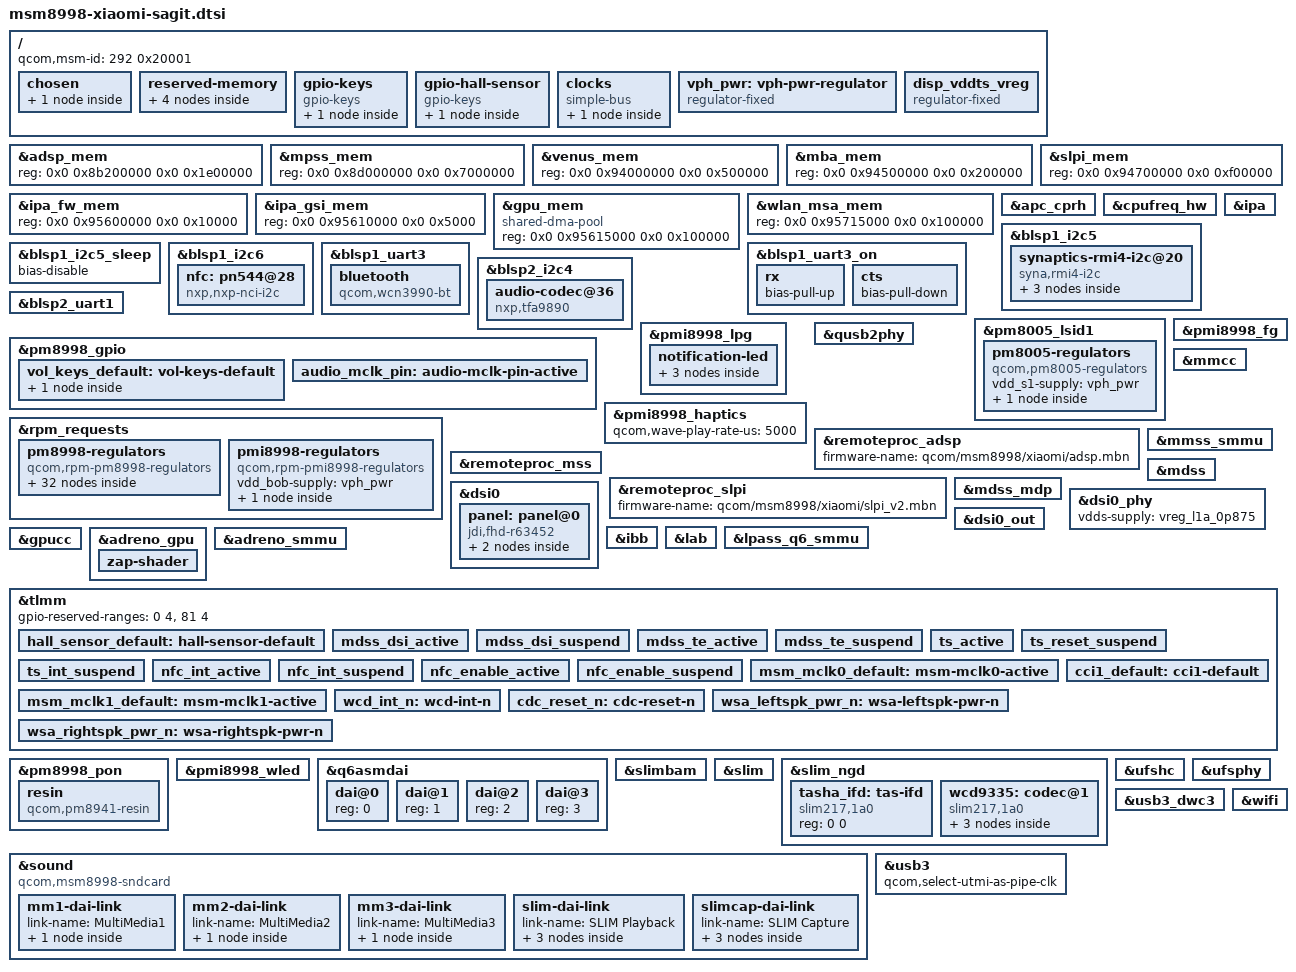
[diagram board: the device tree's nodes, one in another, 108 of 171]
// SPDX-License-Identifier: BSD-3-Clause
/*
 * Xiaomi Mi 6 (sagit) device tree source based on msm8998-mtp.dtsi
 *
 * Copyright (c) 2021, Degdag Mohamed <degdagmohamed@gmail.com>
 * Copyright (c) 2016, The Linux Foundation. All rights reserved.
 */

/dts-v1/;

#include "msm8998.dtsi"
#include "pm8005.dtsi"
#include "pm8998.dtsi"
#include "pmi8998.dtsi"
#include <dt-bindings/gpio/gpio.h>
#include <dt-bindings/input/input.h>
#include <dt-bindings/leds/common.h>
#include <dt-bindings/pinctrl/qcom,pmic-gpio.h>
#include <dt-bindings/sound/qcom,q6afe.h>
#include <dt-bindings/sound/qcom,q6asm.h>

/ {
	/* Required for bootloader to select correct board */
	qcom,msm-id = <292 0x20001>; /* 8998 v2.1 */

	chosen {
		#address-cells = <2>;
		#size-cells = <2>;
		ranges;

		/* Use display framebuffer setup by the UEFI XBL bootloader for simplefb */
		framebuffer0: framebuffer@9d400000 {
			compatible = "simple-framebuffer";
			reg = <0x0 0x9d400000 0x0 0x2400000>;
			width = <1080>;
			height = <1920>;
			stride = <(1080 * 4)>;
			format = "a8r8g8b8";
			status = "disabled";
		};
	};

	reserved-memory {
		/* Bootloader display framebuffer region */
		cont_splash_mem: memory@9d400000 {
			reg = <0x0 0x9d400000 0x0 0x2400000>;
			no-map;
		};

		/* For getting crash logs using Android downstream kernels */
		ramoops@ac000000 {
			compatible = "ramoops";
			reg = <0x0 0xac000000 0x0 0x200000>;
			console-size = <0x80000>;
			pmsg-size = <0x40000>;
			record-size = <0x8000>;
			ftrace-size = <0x20000>;
		};

		/*
		 * The following memory regions on downstream are "dynamically allocated"
		 * but given the same addresses every time. Hard code them as these addresses
		 * are where the Xiaomi signed firmware expects them to be.
		 */
		ipa_fws_region: ipa@f6800000 {
			compatible = "shared-dma-pool";
			reg = <0x0 0xf6800000 0x0 0x5000>;
			no-map;
		};
		zap_shader_region: gpu@f6900000 {
			compatible = "shared-dma-pool";
			reg = <0x0 0xf6900000 0x0 0x2000>;
			no-map;
		};
	};

	gpio-keys {
		compatible = "gpio-keys";
		label = "Volume buttons";
		autorepeat;

		pinctrl-names = "default";
		pinctrl-0 = <&vol_keys_default>;

		vol-down {
			label = "Volume up";
			gpios = <&pm8998_gpio 6 GPIO_ACTIVE_LOW>;
			linux,code = <KEY_VOLUMEUP>;
			debounce-interval = <15>;
			wakeup-source;
		};
	};

	gpio-hall-sensor {
		compatible = "gpio-keys";
		label = "Hall effect sensor";

		pinctrl-names = "default";
		pinctrl-0 = <&hall_sensor_default>;

		hall-sensor {
			label = "Hall Effect Sensor";
			gpios = <&tlmm 124 GPIO_ACTIVE_LOW>;
			linux,input-type = <EV_SW>;
			linux,code = <SW_LID>;
			linux,can-disable;
			wakeup-source;
		};
	};
	
	clocks {
		compatible = "simple-bus";

		div1_mclk: divclk1 {
			compatible = "gpio-gate-clock";
			pinctrl-0 = <&audio_mclk_pin>;
			pinctrl-names = "default";
			clocks = <&rpmcc RPM_SMD_DIV_CLK1>;
			#clock-cells = <0>;
			enable-gpios = <&pm8998_gpio 13 GPIO_ACTIVE_HIGH>;
		};
	};

	vph_pwr: vph-pwr-regulator {
		compatible = "regulator-fixed";
		regulator-name = "vph_pwr";
		regulator-always-on;
		regulator-boot-on;
	};
	
	disp_vddts_vreg: disp_vddts_vreg {
		compatible = "regulator-fixed";
		regulator-name = "disp_vddts_vreg";
		gpio = <&tlmm 50 GPIO_ACTIVE_HIGH>;
		enable-active-high;
		regulator-boot-on;
	};
};

/*
 * Xiaomi' ADSP firmware requires 30 MiB in total, so increase the adsp_mem
 * region by 4 MiB to account for this while relocating the other now
 * conflicting memory nodes accordingly.
 */
&adsp_mem {
	reg = <0x0 0x8b200000 0x0 0x1e00000>;
};
&mpss_mem {
	reg = <0x0 0x8d000000 0x0 0x7000000>;
};
&venus_mem {
	reg = <0x0 0x94000000 0x0 0x500000>;
};
&mba_mem {
	reg = <0x0 0x94500000 0x0 0x200000>;
};
&slpi_mem {
	reg = <0x0 0x94700000 0x0 0xf00000>;
};
&ipa_fw_mem {
	reg = <0x0 0x95600000 0x0 0x10000>;
};
&ipa_gsi_mem {
	reg = <0x0 0x95610000 0x0 0x5000>;
};
&gpu_mem {
	reg = <0x0 0x95615000 0x0 0x100000>;
};
&wlan_msa_mem {
	reg = <0x0 0x95715000 0x0 0x100000>;
};

&apc_cprh {
	status = "ok";
};

&cpufreq_hw {
	status = "ok";
};

&blsp1_i2c5 {
	pinctrl-names = "default", "sleep";
	pinctrl-0 = <&blsp1_i2c5_default>;
	pinctrl-1 = <&blsp1_i2c5_sleep>;
	clock-frequency = <400000>;
	status = "okay";

	synaptics-rmi4-i2c@20 {
		compatible = "syna,rmi4-i2c";
		reg = <0x20>;
		#address-cells = <1>;
		#size-cells = <0>;
		interrupts-extended = <&tlmm 125 0x2008>; /* 0x2008 = IRQF_ONESHOT | IRQF_TRIGGER_LOW */
		pinctrl-names = "default", "sleep";
		pinctrl-0 = <&ts_active>;
		pinctrl-1 = <&ts_int_suspend &ts_reset_suspend>;
		vdd-supply = <&disp_vddts_vreg>;
		vio-supply = <&vreg_l6a_1p8>;
		syna,reset-delay-ms = <200>;
		syna,startup-delay-ms = <200>;

		rmi4-f01@1 {
			reg = <0x01>;
			syna,nosleep-mode = <1>;
		};

		rmi4_f12: rmi4-f12@12 {
			reg = <0x12>;
			touchscreen-x-mm = <64>;
			touchscreen-y-mm = <114>;
			syna,sensor-type = <1>;
			syna,rezero-wait-ms = <200>;
		};
		
		rmi4-f1a@1a {
		reg = <0x1a>;
		syna,codes = <KEY_BACK KEY_APPSELECT>;
		};
	};
};

&blsp1_i2c5_sleep {
	/delete-property/ bias-pull-up;
	/* Configure a no-pull on TP I2C sleep to match downstream. */
	bias-disable;
};

&blsp1_i2c6 {
	status = "okay";

	nfc: pn544@28 {
		compatible = "nxp,nxp-nci-i2c";
		reg = <0x28>;
		clock-frequency = <400000>;

		interrupt-parent = <&tlmm>;
		interrupts = <92 IRQ_TYPE_NONE>;

		enable-gpios = <&tlmm 116 0>;
		firmware-gpios = <&tlmm 93 0>;

		pinctrl-names = "default";
		pinctrl-0 = <&nfc_int_active &nfc_enable_active>;
	};
};

&blsp1_uart3 {
	status = "okay";

	bluetooth {
		compatible = "qcom,wcn3990-bt";

		vddio-supply = <&vreg_s4a_1p8>;
		vddxo-supply = <&vreg_l7a_1p8>;
		vddrf-supply = <&vreg_l17a_1p3>;
		vddch0-supply = <&vreg_l25a_3p3>;
		max-speed = <3200000>;
	};
};

&blsp1_uart3_on {
	rx {
		/delete-property/ bias-disable;
		/*
		 * Configure a pull-up on 46 (RX). This is needed to
		 * avoid garbage data when the TX pin of the Bluetooth
		 * module is in tri-state (module powered off or not
		 * driving the signal yet).
		 */
		bias-pull-up;
	};

	cts {
		/delete-property/ bias-disable;
		/*
		 * Configure a pull-down on 47 (CTS) to match the pull
		 * of the Bluetooth module.
		 */
		bias-pull-down;
	};
};

&blsp2_i2c4 {
	status = "okay";

	audio-codec@36 {
		compatible = "nxp,tfa9890";
		reg = <0x36>;

		/*
		 * vddd-supply = <&vreg_bob>;
		 * vreg_l20a_2p95? 2950000->2960000 mV @ 200->800000 mA?
		 */

		sound-name-prefix = "Mono Speaker";
		#sound-dai-cells = <0>;
		status = "okay";
	};
};

&blsp2_uart1 {
	status = "okay";
};

&ipa {
	status = "okay";

	memory-region = <&ipa_fws_region>; // ipa_fw_mem? ipa_gsi_mem?
	firmware-name = "qcom/msm8998/xiaomi/ipa_fws.mbn";
};

&pm8005_lsid1 {
	pm8005-regulators {
		compatible = "qcom,pm8005-regulators";

		vdd_s1-supply = <&vph_pwr>;

		pm8005_s1: s1 { /* VDD_GFX supply */
			regulator-min-microvolt = <524000>;
			regulator-max-microvolt = <1100000>;
			regulator-enable-ramp-delay = <500>;

			/* hack until we rig up the gpu consumer */
			regulator-always-on;
		};
	};
};

&pm8998_gpio {
	vol_keys_default: vol-keys-default {
		pinconf {
			pins = "gpio6";
			function = "normal";
			bias-pull-up;
			input-enable;
			qcom,drive-strength = <PMIC_GPIO_STRENGTH_NO>;
		};
	};
	
	audio_mclk_pin: audio-mclk-pin-active {
		pins = "gpio13";
		function = "func2";
		power-source = <0>;
	};
};

&pmi8998_fg {
	status = "okay";

	qcom,max-voltage-uv = <4370000>;
	qcom,min-voltage-uv = <3700000>;
	qcom,battery-capacity-ua = <3300000>;
};

&pmi8998_lpg {
	status = "okay";

	//qcom,power-source = <0>;

	notification-led {
		color = <LED_COLOR_ID_RGB>;
		function = LED_FUNCTION_STATUS;

		#address-cells = <1>;
		#size-cells = <0>;

		led@3 {
			reg = <3>;
			color = <LED_COLOR_ID_BLUE>;
		};

		led@4 {
			reg = <4>;
			color = <LED_COLOR_ID_GREEN>;
		};

		led@5 {
			reg = <5>;
			color = <LED_COLOR_ID_RED>;
		};
	};
};

&pmi8998_haptics {
	status = "okay";

	qcom,wave-play-rate-us = <5000>;
};

&qusb2phy {
	status = "okay";

	vdda-pll-supply = <&vreg_l12a_1p8>;
	vdda-phy-dpdm-supply = <&vreg_l24a_3p075>;
};

&rpm_requests {
	pm8998-regulators {
		compatible = "qcom,rpm-pm8998-regulators";

		vdd_s1-supply = <&vph_pwr>;
		vdd_s2-supply = <&vph_pwr>;
		vdd_s3-supply = <&vph_pwr>;
		vdd_s4-supply = <&vph_pwr>;
		vdd_s5-supply = <&vph_pwr>;
		vdd_s6-supply = <&vph_pwr>;
		vdd_s7-supply = <&vph_pwr>;
		vdd_s8-supply = <&vph_pwr>;
		vdd_s9-supply = <&vph_pwr>;
		vdd_s10-supply = <&vph_pwr>;
		vdd_s11-supply = <&vph_pwr>;
		vdd_s12-supply = <&vph_pwr>;
		vdd_s13-supply = <&vph_pwr>;
		vdd_l1_l27-supply = <&vreg_s7a_1p025>;
		vdd_l2_l8_l17-supply = <&vreg_s3a_1p35>;
		vdd_l3_l11-supply = <&vreg_s7a_1p025>;
		vdd_l4_l5-supply = <&vreg_s7a_1p025>;
		vdd_l6-supply = <&vreg_s5a_2p04>;
		vdd_l7_l12_l14_l15-supply = <&vreg_s5a_2p04>;
		vdd_l9-supply = <&vreg_bob>;
		vdd_l10_l23_l25-supply = <&vreg_bob>;
		vdd_l13_l19_l21-supply = <&vreg_bob>;
		vdd_l16_l28-supply = <&vreg_bob>;
		vdd_l18_l22-supply = <&vreg_bob>;
		vdd_l20_l24-supply = <&vreg_bob>;
		vdd_l26-supply = <&vreg_s3a_1p35>;
		vdd_lvs1_lvs2-supply = <&vreg_s4a_1p8>;

		vreg_s3a_1p35: s3 {
			regulator-min-microvolt = <1352000>;
			regulator-max-microvolt = <1352000>;
		};
		vreg_s4a_1p8: s4 {
			regulator-min-microvolt = <1800000>;
			regulator-max-microvolt = <1800000>;
			regulator-allow-set-load;
		};
		vreg_s5a_2p04: s5 {
			regulator-min-microvolt = <1904000>;
			regulator-max-microvolt = <2040000>;
		};
		vreg_s7a_1p025: s7 {
			regulator-min-microvolt = <900000>;
			regulator-max-microvolt = <1028000>;
		};
		vreg_l1a_0p875: l1 {
			regulator-min-microvolt = <880000>;
			regulator-max-microvolt = <880000>;
		};
		vreg_l2a_1p2: l2 {
			regulator-min-microvolt = <1200000>;
			regulator-max-microvolt = <1200000>;
		};
		vreg_l3a_1p0: l3 {
			regulator-min-microvolt = <1000000>;
			regulator-max-microvolt = <1000000>;
		};
		vreg_l5a_0p8: l5 {
			regulator-min-microvolt = <800000>;
			regulator-max-microvolt = <800000>;
		};
		vreg_l6a_1p8: l6 {
			regulator-min-microvolt = <1800000>;
			regulator-max-microvolt = <1800000>;
		};
		vreg_l7a_1p8: l7 {
			regulator-min-microvolt = <1800000>;
			regulator-max-microvolt = <1800000>;
		};
		vreg_l8a_1p2: l8 {
			regulator-min-microvolt = <1200000>;
			regulator-max-microvolt = <1200000>;
		};
		vreg_l9a_1p8: l9 {
			regulator-min-microvolt = <1808000>;
			regulator-max-microvolt = <2960000>;
		};
		vreg_l10a_1p8: l10 {
			regulator-min-microvolt = <1808000>;
			regulator-max-microvolt = <2960000>;
		};
		vreg_l11a_1p0: l11 {
			regulator-min-microvolt = <1000000>;
			regulator-max-microvolt = <1000000>;
		};
		vreg_l12a_1p8: l12 {
			regulator-min-microvolt = <1800000>;
			regulator-max-microvolt = <1800000>;
		};
		vreg_l13a_2p95: l13 {
			regulator-min-microvolt = <1808000>;
			regulator-max-microvolt = <2960000>;
		};
		vreg_l14a_1p8: l14 {
			regulator-min-microvolt = <1800000>;
			regulator-max-microvolt = <1800000>;
		};
		vreg_l15a_1p8: l15 {
			regulator-min-microvolt = <1800000>;
			regulator-max-microvolt = <1800000>;
		};
		vreg_l16a_2p7: l16 {
			regulator-min-microvolt = <2704000>;
			regulator-max-microvolt = <2704000>;
		};
		vreg_l17a_1p3: l17 {
			regulator-min-microvolt = <1304000>;
			regulator-max-microvolt = <1304000>;
		};
		vreg_l18a_2p7: l18 {
			regulator-min-microvolt = <2704000>;
			regulator-max-microvolt = <2704000>;
		};
		vreg_l19a_3p0: l19 {
			regulator-min-microvolt = <3008000>;
			regulator-max-microvolt = <3008000>;
		};
		vreg_l20a_2p95: l20 {
			regulator-min-microvolt = <2960000>;
			regulator-max-microvolt = <2960000>;
			regulator-allow-set-load;
		};
		vreg_l21a_2p95: l21 {
			regulator-min-microvolt = <2960000>;
			regulator-max-microvolt = <2960000>;
			regulator-allow-set-load;
			regulator-system-load = <800000>;
		};
		vreg_l22a_2p85: l22 {
			regulator-min-microvolt = <2864000>;
			regulator-max-microvolt = <2864000>;
		};
		vreg_l23a_3p3: l23 {
			regulator-min-microvolt = <3312000>;
			regulator-max-microvolt = <3312000>;
		};
		vreg_l24a_3p075: l24 {
			regulator-min-microvolt = <3088000>;
			regulator-max-microvolt = <3088000>;
		};
		vreg_l25a_3p3: l25 {
			regulator-min-microvolt = <3104000>;
			regulator-max-microvolt = <3312000>;
		};
		vreg_l26a_1p2: l26 {
			regulator-min-microvolt = <1200000>;
			regulator-max-microvolt = <1200000>;
			regulator-allow-set-load;
		};
		vreg_l28_3p0: l28 {
			regulator-min-microvolt = <3008000>;
			regulator-max-microvolt = <3008000>;
		};
		vreg_lvs1a_1p8: lvs1 { };
		vreg_lvs2a_1p8: lvs2 { };
	};

	pmi8998-regulators {
		compatible = "qcom,rpm-pmi8998-regulators";

		vdd_bob-supply = <&vph_pwr>;

		vreg_bob: bob {
			regulator-min-microvolt = <3312000>;
			regulator-max-microvolt = <3800000>;
		};
	};
};

&remoteproc_adsp {
	status = "okay";

	firmware-name = "qcom/msm8998/xiaomi/adsp.mbn";
};

&remoteproc_mss {
	status = "okay";

	firmware-name = "qcom/msm8998/xiaomi/mba.mbn", "qcom/msm8998/xiaomi/modem.mbn";
};

&remoteproc_slpi {
	status = "okay";

	firmware-name = "qcom/msm8998/xiaomi/slpi_v2.mbn";
};

&mmcc {
	status = "okay";
};

&mmss_smmu {
	status = "okay";
};

&mdss {
	status = "okay";
};

&mdss_mdp {
	status = "okay";
};

&dsi0 {
	#address-cells = <1>;
	#size-cells = <0>;
	status = "ok";

	vdd-supply = <&vreg_l1a_0p875>;
	vdda-supply = <&vreg_l2a_1p2>;

	panel: panel@0 {
		compatible = "jdi,fhd-r63452";
		reg = <0>;
		
		backlight = <&pmi8998_wled>;
		reset-gpios = <&tlmm 94 GPIO_ACTIVE_LOW>;
		disp-te-gpios = <&tlmm 10 GPIO_ACTIVE_LOW>;

		ibb-supply = <&ibb>;
		lab-supply = <&lab>;
		vddio-supply = <&vreg_l14a_1p8>;

		pinctrl-names = "default", "sleep";
		pinctrl-0 = <&mdss_dsi_active &mdss_te_active>;
		pinctrl-1 = <&mdss_dsi_suspend &mdss_te_suspend>;
		port {
			panel_in: endpoint {
				remote-endpoint = <&dsi0_out>;
			};
		};
	};
};

&dsi0_phy {
	status = "okay";
	vdds-supply = <&vreg_l1a_0p875>;
};

&dsi0_out {
	remote-endpoint = <&panel_in>;
	data-lanes = <0 1 2 3>;
};

&ibb {
	regulator-min-microvolt = <4600000>;
	regulator-max-microvolt = <6000000>;
	regulator-min-microamp = <800000>;
	regulator-max-microamp = <800000>;
	regulator-enable-ramp-delay = <200>;
	regulator-over-current-protection;
	regulator-pull-down;
	regulator-ramp-delay = <1>;
	regulator-settling-time-up-us = <600>;
	regulator-settling-time-down-us = <1000>;
	regulator-soft-start;
	qcom,discharge-resistor-kohms = <300>;
};

&lab {
	regulator-min-microvolt = <4600000>;
	regulator-max-microvolt = <6000000>;
	qcom,soft-start-us = <800>;
	regulator-min-microamp = <200000>;
	regulator-max-microamp = <200000>;
	regulator-enable-ramp-delay = <500>;
	regulator-over-current-protection;
	regulator-pull-down;
	regulator-ramp-delay = <1>;
	regulator-settling-time-up-us = <50000>;
	regulator-settling-time-down-us = <3000>;
	regulator-soft-start;
};

&lpass_q6_smmu {
	qcom,bypass-cbndx = /bits/ 8 <11>;
	qcom,reset-nodisable-cbs = /bits/ 8 <12>;

	status = "ok";
};

/* Adreno 540 GPU */
&gpucc {
	status = "ok";
};

&gpu_mem {
	compatible = "shared-dma-pool";
};

&adreno_gpu {
	status = "ok";

	zap-shader {
		memory-region = <&zap_shader_region>; // gpu_mem?
		firmware-name = "qcom/a540_zap.mbn";
	};
};

&adreno_smmu {
	status = "ok";
};

/*
 * HACK: Shoot GPU voltage high to stabilize Adreno 540 at high frequencies
 *       until the GPU CPR is brought up.
 */
&pm8005_s1 {
	regulator-min-microvolt = <1088000>; /* 0,524V -> 0,988V */
	//regulator-max-microvolt = <1100000>;
};

&tlmm {
	gpio-reserved-ranges = <0 4>, <81 4>;

	hall_sensor_default: hall-sensor-default {
		pins = "gpio124";
		function = "gpio";
		drive-strength = <2>;
		bias-disable;
		input-enable;
	};
	mdss_dsi_active: mdss_dsi_active {
		pins = "gpio94";
		function = "gpio";
		drive-strength = <8>; /* 8 mA */
		bias-disable = <0>; /* no pull */
	};
			
	mdss_dsi_suspend: mdss_dsi_suspend {
		pins = "gpio94";
		function = "gpio";
		drive-strength = <2>; /* 2 mA */
		bias-pull-down; /* pull down */
	};
	
	mdss_te_active: mdss_te_active {
		pins = "gpio10";
		function = "mdp_vsync_a";
		drive-strength = <2>; /* 8 mA */
		bias-pull-down; /* pull down*/
	};

	mdss_te_suspend: mdss_te_suspend {
		pins = "gpio10";
		function = "mdp_vsync_a";
		drive-strength = <2>; /* 2 mA */
		bias-pull-down; /* pull down */
	};

	ts_active: ts_active {
		pins = "gpio89", "gpio125";
		function = "gpio";
		drive-strength = <16>;
		bias-pull-up;
		input-enable;
	};

	ts_reset_suspend: ts_reset_suspend {
		pins = "gpio89";
		function = "gpio";
		drive-strength = <2>;
		bias-disable;
	};

	ts_int_suspend: ts_int_suspend {
		pins = "gpio125";
		function = "gpio";
		drive-strength = <2>;
		bias-disable;
	};

	nfc_int_active: nfc_int_active {
		pins = "gpio92";
		function = "gpio";
		drive-strength = <6>;
		bias-pull-up;
	};

	nfc_int_suspend: nfc_int_suspend {
		pins = "gpio92";
		function = "gpio";
		drive-strength = <6>;
		bias-pull-up;
	};

	nfc_enable_active: nfc_enable_active {
		pins = "gpio12", "gpio116";
		function = "gpio";
		drive-strength = <6>;
		bias-pull-up;
	};

	nfc_enable_suspend: nfc_enable_suspend {
		pins = "gpio12", "gpio116";
		function = "gpio";
		drive-strength = <6>;
		bias-disable;
	};
	
	msm_mclk0_default: msm-mclk0-active {
		pins = "gpio13";
		function = "cam_mclk";
		drive-strength = <2>;
		bias-disable;
	};

	msm_mclk1_default: msm-mclk1-active {
		pins = "gpio14";
		function = "cam_mclk";
		drive-strength = <2>;
		bias-disable;
	};

	cci1_default: cci1-default {
		pins = "gpio18", "gpio19";
		function = "cci_i2c";
		bias-disable;
		drive-strength = <2>;
	};

	cci1_default: cci1-default {
		pins = "gpio19", "gpio20";
		function = "cci_i2c";
		bias-disable;
		drive-strength = <2>;
	};
	
	wcd_int_n: wcd-int-n {
		pins = "gpio54";
		function = "gpio";
		bias-pull-down;
		drive-strength = <2>;
		input-enable;
	};

	cdc_reset_n: cdc-reset-n {
		pins = "gpio64";
		function = "gpio";
		bias-pull-down;
		drive-strength = <16>;
		output-high;
	};

	wsa_leftspk_pwr_n: wsa-leftspk-pwr-n {
		pins = "gpio65";
		function = "gpio";
		bias-disable;
		drive-strength = <2>;
		output-low;
	};

	wsa_rightspk_pwr_n: wsa-rightspk-pwr-n {
		pins = "gpio66";
		function = "gpio";
		bias-disable;
		drive-strength = <2>;
		output-low;
	};
};

&pm8998_pon {
	resin {
		compatible = "qcom,pm8941-resin";
		interrupts = <GIC_SPI 0x8 1 IRQ_TYPE_EDGE_BOTH>;
		debounce = <15625>;
		bias-pull-up;
		linux,code = <KEY_VOLUMEDOWN>;
	};
};

&pmi8998_wled {
	status = "okay";

	default-brightness = <800>;
	qcom,switching-freq = <800>;
	qcom,ovp-millivolt = <29600>;
	qcom,current-boost-limit = <970>;
	qcom,current-limit-microamp = <25000>;
	qcom,num-strings = <4>;
	qcom,enabled-strings = <0 1 2 3>;
};

&q6asmdai {
	dai@0 {
		reg = <0>;
	};

	dai@1 {
		reg = <1>;
	};

	dai@2 {
		reg = <2>;
	};
	dai@3 {
		reg = <3>;
//		direction = <2>;
//		is-compress-dai;
	};
};

&slimbam {
	status = "okay";
};

&slim {
	status = "okay";
};

&slim_ngd {
	tasha_ifd: tas-ifd {
		compatible = "slim217,1a0";
		reg  = <0 0>;
	};

	wcd9335: codec@1{
		compatible = "slim217,1a0";
		reg  = <1 0>;

		clock-names = "mclk", "slimbus";
		clocks = <&div1_mclk>,
			 <&rpmcc RPM_SMD_LN_BB_CLK1>;
		#clock-cells = <0>;

		interrupt-parent = <&tlmm>;
		interrupts = <54 IRQ_TYPE_LEVEL_HIGH>,
			     <53 IRQ_TYPE_LEVEL_HIGH>;
		interrupt-names  = "intr1", "intr2";
		interrupt-controller;
		#interrupt-cells = <1>;

		reset-gpios = <&tlmm 64 GPIO_ACTIVE_HIGH>;

		slim-ifc-dev  = <&tasha_ifd>;

		vdd-buck-supply = <&vreg_s4a_1p8>;
		vdd-buck-sido-supply = <&vreg_s4a_1p8>;
		vdd-tx-supply = <&vreg_s4a_1p8>;
		vdd-rx-supply = <&vreg_s4a_1p8>;
		vdd-io-supply = <&vreg_s4a_1p8>;
		qcom,mbhc-vthreshold = <1700>;

		/* On SoMC Yoshino, HPHL is normally open, GND normally closed */
		qcom,hphl-jack-type-normally-open;
		//qcom,gnd-jack-type-normally-open;

		#address-cells = <1>;
		#size-cells = <1>;
		#sound-dai-cells = <1>;

		swm: swm@c85 {
			compatible = "qcom,soundwire-v1.3.0";
			reg = <0xc85 0x40>;
			interrupts-extended = <&wcd9335 13>;

			qcom,dout-ports	= <6>;
			qcom,din-ports	= <2>;
			qcom,ports-sinterval-low =/bits/ 8  <0x07 0x1F 0x3F 0x7 0x1F 0x3F 0x0F 0x0F>;
			qcom,ports-offset1 = /bits/ 8 <0x01 0x02 0x0C 0x6 0x12 0x0D 0x07 0x0A >;
			qcom,ports-offset2 = /bits/ 8 <0x00 0x00 0x1F 0x00 0x00 0x1F 0x00 0x00>;
						    /*downstream is <0xFF 0x00 0x1F 0xFF 0x00 0x1F 0x00 0x00>;*/
			qcom,ports-block-pack-mode = /bits/ 8 <0xFF 0xFF 0x01 0xFF 0xFF 0x01 0xFF 0xFF>;
			clocks = <&xo>;
			clock-names = "iface";
			#address-cells = <2>;
			#size-cells = <0>;
			#sound-dai-cells = <1>;

			left_spkr: wsa8810-left {
				compatible = "sdw10217201000";
				reg = <0 1>;
				powerdown-gpios = <&tlmm 65 GPIO_ACTIVE_HIGH>;
				pinctrl-0 = <&wsa_leftspk_pwr_n>;
				pinctrl-names = "default";
				#thermal-sensor-cells = <0>;
				sound-name-prefix = "SpkrRight";
				#sound-dai-cells = <0>;
			};

			right_spkr: wsa8810-right {
				compatible = "sdw10217201000";
				powerdown-gpios = <&tlmm 66 GPIO_ACTIVE_HIGH>;
				reg = <0 2>;
				pinctrl-0 = <&wsa_rightspk_pwr_n>;
				pinctrl-names = "default";
				#thermal-sensor-cells = <0>;
				sound-name-prefix = "SpkrLeft";
				#sound-dai-cells = <0>;
			};
		};
	};
};

&sound {
	compatible = "qcom,msm8998-sndcard";
	model = "msm8988-Xiaomi-Mi6";

	/* Audio routing including WSA amp speakers */
	/*audio-routing = "AIF4 VI", "MCLK",
			"RX_BIAS", "MCLK",
			"MADINPUT", "MCLK",
			"AMIC1", "MIC BIAS2",
			"MIC BIAS2", "Handset Mic",
			"AMIC2", "MIC BIAS2",
			"MIC BIAS2", "Headset Mic",
			"AMIC3", "MIC BIAS1",
			"MIC BIAS1", "ANCRight Headset Mic",
			"AMIC4", "MIC BIAS1",
			"MIC BIAS1", "ANCLeft Headset Mic",
			"AMIC5", "MIC BIAS4",
			"MIC BIAS4", "Handset Mic",
			"AMIC6", "MIC BIAS4",
			"MIC BIAS4", "Analog Mic6";*/

	/* Basic routing, 3.5mm jack only */
	audio-routing = "RX_BIAS", "MCLK",
			"AMIC2", "MIC BIAS2",
			"AMIC3", "MIC BIAS3",
			"DMIC0", "MIC BIAS1",
			"DMIC4", "MIC BIAS4",
			"MM_DL1", "MultiMedia1 Playback",
			"MM_DL2", "MultiMedia2 Playback",
			"MultiMedia3 Capture", "MM_UL3";

/*
   <path name="voicemmode1-call headphones">
        <ctl name="SLIM_0_RX_Voice Mixer VoiceMMode1" value="1" />
        <ctl name="VoiceMMode1_Tx Mixer SLIM_0_TX_MMode1" value="1" />
    </path>

    <path name="sidetone-headphones">
        <path name="sidetone-iir" />
        <!-- 45 % of 124 (range 0 - 124) Register: 0x340 -->
        <ctl name="IIR0 INP0 Volume" value="44" />
        <ctl name="RX INT1 MIX2 INP" value="SRC0" />
        <ctl name="RX INT2 MIX2 INP" value="SRC0" />
    </path>

    <path name="speaker-and-headphones">
        <path name="speaker" />
        <ctl name="RX INT1_1 MIX1 INP0" value="RX1" />
        <ctl name="RX INT2_1 MIX1 INP0" value="RX1" />
        <ctl name="RX INT1 DEM MUX" value="CLSH_DSM_OUT" />
        <ctl name="RX INT2 DEM MUX" value="CLSH_DSM_OUT" />
        <ctl name="RX1 Digital Volume" value="55" />
        <ctl name="RX2 Digital Volume" value="55" />
        <path name="headphones-hpf" />
        <ctl name="Set Custom Stereo" value="Mix" />
    </path>

    <path name="headphones">
        <ctl name="SLIM RX0 MUX" value="AIF_MIX1_PB" />
        <ctl name="SLIM RX1 MUX" value="AIF_MIX1_PB" />
        <ctl name="SLIM_0_RX Channels" value="Two" />
        <ctl name="RX INT1_1 MIX1 INP0" value="RX0" />
        <ctl name="RX INT2_1 MIX1 INP0" value="RX1" />
        <ctl name="RX INT1 DEM MUX" value="CLSH_DSM_OUT" />
        <ctl name="RX INT2 DEM MUX" value="CLSH_DSM_OUT" />
        <ctl name="RX1 Digital Volume" value="80" />
        <ctl name="RX2 Digital Volume" value="80" />
    </path>

    <path name="headphones-hpf">
        <ctl name="RX INT1_1 HPF cut off" value="CF_NEG_3DB_150HZ" />
        <ctl name="RX INT2_1 HPF cut off" value="CF_NEG_3DB_150HZ" />
    </path>


    <path name="anc-off-headphone">
        <ctl name="SLIM RX0 MUX" value="AIF_MIX1_PB" />
        <ctl name="SLIM RX1 MUX" value="AIF_MIX1_PB" />
        <ctl name="SLIM_0_RX Channels" value="Two" />
        <ctl name="RX INT1_1 MIX1 INP0" value="RX0" />
        <ctl name="RX INT2_1 MIX1 INP0" value="RX1" />
        <ctl name="RX INT1 DEM MUX" value="CLSH_DSM_OUT" />
        <ctl name="RX INT2 DEM MUX" value="CLSH_DSM_OUT" />
        <ctl name="COMP1 Switch" value="0" />
        <ctl name="COMP2 Switch" value="0" />
        <ctl name="HPHL Volume" value="20" />
        <ctl name="HPHR Volume" value="20" />
        <ctl name="RX1 Digital Volume" value="77" />
        <ctl name="RX2 Digital Volume" value="77" />
    </path>

    <path name="audio-record">
        <ctl name="MultiMedia1 Mixer SLIM_0_TX" value="1" />
    </path>

   <path name="deep-buffer-playback">
        <ctl name="SLIMBUS_0_RX Audio Mixer MultiMedia1" value="1" />
    </path>
*/

	mm1-dai-link {
		/* Deep Buffer playback for SLIM{0,7}, BT, USBAUDIO, AFE, DP, HDMI */
		link-name = "MultiMedia1";
		cpu {
			sound-dai = <&q6asmdai  MSM_FRONTEND_DAI_MULTIMEDIA1>;
		};
	};

	mm2-dai-link {
		/* Multichannel playback for HDMI and DP */
		link-name = "MultiMedia2";
		cpu {
			sound-dai = <&q6asmdai  MSM_FRONTEND_DAI_MULTIMEDIA2>;
		};
	};

	mm3-dai-link {
		/* Ultra Low Latency playback for SLIM0, HDMI, and DP */
		link-name = "MultiMedia3";
		cpu {
			sound-dai = <&q6asmdai  MSM_FRONTEND_DAI_MULTIMEDIA3>;
		};
	};

	slim-dai-link {
		link-name = "SLIM Playback";
		cpu {
			sound-dai = <&q6afedai SLIMBUS_0_RX>;
		};

		platform {
			sound-dai = <&q6routing>;
		};

		codec {
			/* Support only sound through 3.5mm for now: soundwire is currently unavailable */
			//sound-dai =  <&left_spkr>, <&right_spkr>, <&swm 0>, <&wcd9335 0>;
			sound-dai =  <&wcd9335 0>;
		};
	};

	slimcap-dai-link {
		link-name = "SLIM Capture";
		cpu {
			sound-dai = <&q6afedai SLIMBUS_0_TX>;
		};

		platform {
			sound-dai = <&q6routing>;
		};

		codec {
			sound-dai = <&wcd9335 1>;
		};
	};
};

&ufshc {
	status = "okay";

	vcc-supply = <&vreg_l20a_2p95>;
	vccq-supply = <&vreg_l26a_1p2>;
	vccq2-supply = <&vreg_s4a_1p8>;
	vcc-max-microamp = <750000>;
	vccq-max-microamp = <560000>;
	vccq2-max-microamp = <750000>;
};

&ufsphy {
	status = "okay";

	vdda-phy-supply = <&vreg_l1a_0p875>;
	vdda-pll-supply = <&vreg_l2a_1p2>;
	vddp-ref-clk-supply = <&vreg_l26a_1p2>;
	vdda-phy-max-microamp = <51400>;
	vdda-pll-max-microamp = <14600>;
	vddp-ref-clk-max-microamp = <100>;
	vddp-ref-clk-always-on;
};

&usb3 {
	status = "okay";

	/* Disable USB3 clock requirement as the device only supports USB2 */
	qcom,select-utmi-as-pipe-clk;
};

&usb3_dwc3 {
	/* Drop the unused USB 3 PHY */
	phys = <&qusb2phy>;
	phy-names = "usb2-phy";

	/* Fastest mode for USB 2 */
	maximum-speed = "high-speed";

	/* Force to peripheral until we can switch modes */
	dr_mode = "peripheral";
};

&wifi {
	status = "okay";
	vdd-0.8-cx-mx-supply = <&vreg_l5a_0p8>;
	vdd-1.8-xo-supply = <&vreg_l7a_1p8>;
	vdd-1.3-rfa-supply = <&vreg_l17a_1p3>;
	vdd-3.3-ch0-supply = <&vreg_l25a_3p3>;
};
